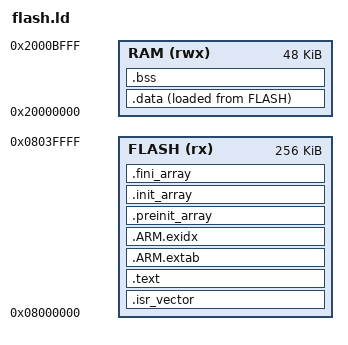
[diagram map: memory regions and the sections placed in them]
/* Internal flash and SRAM of the GD32F103RCT6. */
ENTRY(Reset_Handler)

MEMORY
{
    FLASH (rx)  : ORIGIN = 0x08000000, LENGTH = 256K
    RAM   (rwx) : ORIGIN = 0x20000000, LENGTH = 48K
}

_estack = ORIGIN(RAM) + LENGTH(RAM);
_Min_Stack_Size = 0x400;

PHDRS
{
    flash PT_LOAD FLAGS(5);
    ram PT_LOAD FLAGS(6);
}

SECTIONS
{
    .isr_vector :
    {
        __isr_vector_start = .;
        KEEP(*(.isr_vector))
        __isr_vector_end = .;
    } > FLASH :flash

    .text :
    {
        *(.text .text.*)
        *(.rodata .rodata.*)
        *(.glue_7 .glue_7t)
        KEEP(*(.init))
        KEEP(*(.fini))
        . = ALIGN(4);
    } > FLASH

    .ARM.extab :
    {
        *(.ARM.extab* .gnu.linkonce.armextab.*)
    } > FLASH

    .ARM.exidx :
    {
        __exidx_start = .;
        *(.ARM.exidx* .gnu.linkonce.armexidx.*)
        __exidx_end = .;
    } > FLASH

    .preinit_array :
    {
        PROVIDE_HIDDEN(__preinit_array_start = .);
        KEEP(*(.preinit_array))
        PROVIDE_HIDDEN(__preinit_array_end = .);
    } > FLASH

    .init_array :
    {
        PROVIDE_HIDDEN(__init_array_start = .);
        KEEP(*(SORT_BY_INIT_PRIORITY(.init_array.*)))
        KEEP(*(.init_array))
        PROVIDE_HIDDEN(__init_array_end = .);
    } > FLASH

    .fini_array :
    {
        PROVIDE_HIDDEN(__fini_array_start = .);
        KEEP(*(SORT_BY_INIT_PRIORITY(.fini_array.*)))
        KEEP(*(.fini_array))
        PROVIDE_HIDDEN(__fini_array_end = .);
    } > FLASH

    _sidata = LOADADDR(.data);
    .data :
    {
        . = ALIGN(4);
        _sdata = .;
        *(.data .data.*)
        . = ALIGN(4);
        _edata = .;
    } > RAM AT > FLASH :ram

    .bss (NOLOAD) :
    {
        . = ALIGN(4);
        _sbss = .;
        __bss_start__ = .;
        *(.bss .bss.*)
        *(COMMON)
        . = ALIGN(4);
        _ebss = .;
        __bss_end__ = .;
        . = ALIGN(8);
        PROVIDE(end = .);
        PROVIDE(_end = .);
    } > RAM :ram

    .ARM.attributes 0 : { *(.ARM.attributes) } :NONE
}

ASSERT(ADDR(.bss) + SIZEOF(.bss) + _Min_Stack_Size <= _estack, "Not enough SRAM for the stack")
